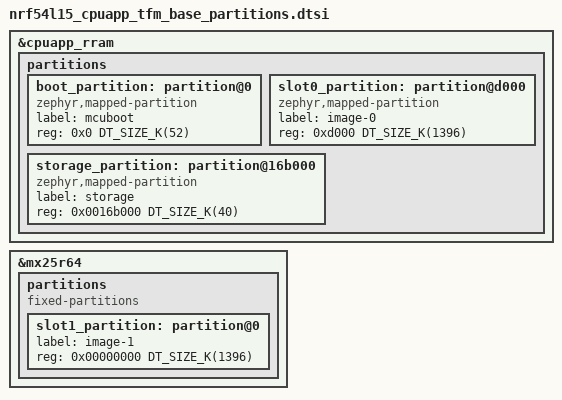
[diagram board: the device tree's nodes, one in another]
/*
 * Copyright (c) 2026 Nordic Semiconductor ASA
 *
 * SPDX-License-Identifier: LicenseRef-Nordic-5-Clause
 */

/delete-node/ &slot0_partition;
/delete-node/ &storage_partition;

&cpuapp_rram {
	partitions {
		ranges;
		#address-cells = <1>;
		#size-cells = <1>;

		boot_partition: partition@0 {
			compatible = "zephyr,mapped-partition";
			label = "mcuboot";
			reg = <0x0 DT_SIZE_K(52)>;
		};

		slot0_partition: partition@d000 {
			compatible = "zephyr,mapped-partition";
			label = "image-0";
			reg = <0xd000 DT_SIZE_K(1396)>;
			ranges = <0x0 0xd000 DT_SIZE_K(1396)>;
			#address-cells = <1>;
			#size-cells = <1>;
		};

		storage_partition: partition@16b000 {
			compatible = "zephyr,mapped-partition";
			label = "storage";
			reg = <0x0016b000 DT_SIZE_K(40)>;
		};
	};
};

&mx25r64 {
	status = "okay";

	partitions {
		compatible = "fixed-partitions";
		#address-cells = <1>;
		#size-cells = <1>;

		slot1_partition: partition@0 {
			label = "image-1";
			reg = <0x00000000 DT_SIZE_K(1396)>;
		};
	};
};
